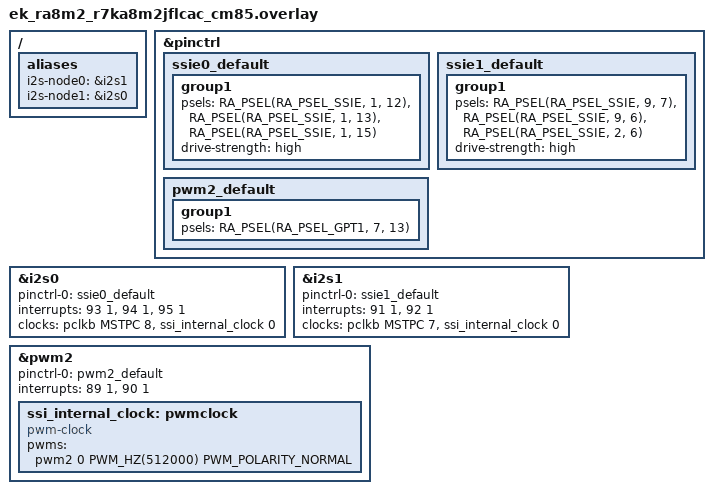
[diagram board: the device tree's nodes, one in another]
/*
 * Copyright (c) 2025 Renesas Electronics Corporation
 *
 * SPDX-License-Identifier: Apache-2.0
 */

#include <zephyr/dt-bindings/pwm/pwm.h>

/ {
	aliases {
		i2s-node0 = &i2s1;
		i2s-node1 = &i2s0;
	};
};

&pinctrl {
	ssie0_default: ssie0_default {
		group1 {
			/* SSI_BCK SSI_LRCK SSI_TX */
			psels = <RA_PSEL(RA_PSEL_SSIE, 1, 12)>,
				<RA_PSEL(RA_PSEL_SSIE, 1, 13)>,
				<RA_PSEL(RA_PSEL_SSIE, 1, 15)>;
			drive-strength = "high";
		};
	};

	ssie1_default: ssie1_default {
		group1 {
			/* SSI_BCK SSI_LRCK SSI_DATA */
			psels = <RA_PSEL(RA_PSEL_SSIE, 9, 7)>,
				<RA_PSEL(RA_PSEL_SSIE, 9, 6)>,
				<RA_PSEL(RA_PSEL_SSIE, 2, 6)>;
			drive-strength = "high";
		};
	};

	pwm2_default: pwm2_default {
		group1 {
			/* GTIOC2A */
			psels = <RA_PSEL(RA_PSEL_GPT1, 7, 13)>;
		};
	};
};

&i2s0 {
	pinctrl-0 = <&ssie0_default>;
	pinctrl-names = "default";
	interrupts = <93 1>, <94 1>, <95 1>;
	interrupt-names = "ssi_txi", "ssi_rxi", "ssi_if";
	status = "okay";
	clocks = <&pclkb MSTPC 8>, <&ssi_internal_clock 0>;
	clock-names = "pclk", "audio-clock";
};

&i2s1 {
	pinctrl-0 = <&ssie1_default>;
	pinctrl-names = "default";
	interrupts = <91 1>, <92 1>;
	interrupt-names = "ssi_rt", "ssi_if";
	status = "okay";
	clocks = <&pclkb MSTPC 7>, <&ssi_internal_clock 0>;
	clock-names = "pclk", "audio-clock";
};

&pwm2 {
	pinctrl-0 = <&pwm2_default>;
	pinctrl-names = "default";
	interrupts = <89 1>, <90 1>;
	interrupt-names = "gtioca", "overflow";
	status = "okay";

	ssi_internal_clock: pwmclock {
		status = "okay";
		compatible = "pwm-clock";
		#clock-cells = <1>;
		pwms = <&pwm2 0 PWM_HZ(512000) PWM_POLARITY_NORMAL>;
	};
};
